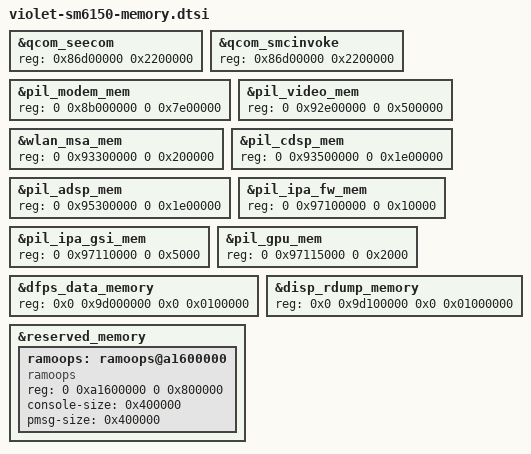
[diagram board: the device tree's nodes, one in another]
/*
 * Copyright (C) 2020 The LineageOS Project
 *
 * this file is for attribution only of violet
 * And public attribution of Xiaomi platforms (like F7B and so)
 */

&qcom_seecom {
    reg = <0x86d00000 0x2200000>;
};

&qcom_smcinvoke {
    reg = <0x86d00000 0x2200000>;
};

&pil_modem_mem {
    reg = <0 0x8b000000 0 0x7e00000>;
};

&pil_video_mem {
    reg = <0 0x92e00000 0 0x500000>;
};

&wlan_msa_mem {
    reg = <0 0x93300000 0 0x200000>;
};

&pil_cdsp_mem {
    reg = <0 0x93500000 0 0x1e00000>;
};

&pil_adsp_mem {
    reg = <0 0x95300000 0 0x1e00000>;
};

&pil_ipa_fw_mem {
    reg = <0 0x97100000 0 0x10000>;
};

&pil_ipa_gsi_mem {
    reg = <0 0x97110000 0 0x5000>;
};

&pil_gpu_mem {
    reg = <0 0x97115000 0 0x2000>;
};

&dfps_data_memory {
    reg = <0x0 0x9d000000 0x0 0x0100000>;
};

&disp_rdump_memory{
    reg = <0x0 0x9d100000 0x0 0x01000000>;
};

&reserved_memory {
    ramoops: ramoops@a1600000 {
        compatible = "ramoops";
        reg = <0 0xa1600000 0 0x800000>;
        console-size = <0x400000>;
        pmsg-size = <0x400000>;
    };
};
